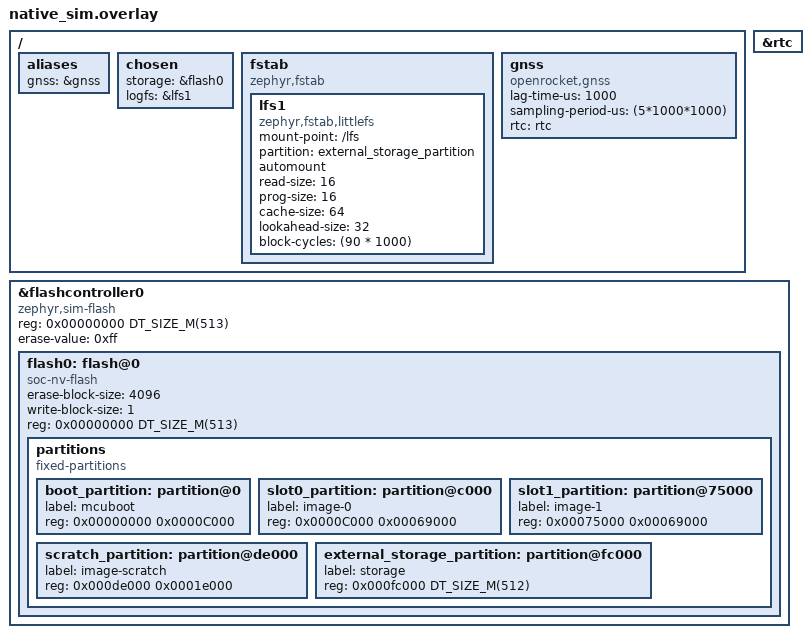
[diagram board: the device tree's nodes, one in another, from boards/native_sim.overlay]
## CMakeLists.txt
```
#-------------------------------------------------------------------------------
# Backplane Radio Module Application
#
# Copyright (c) 2023 Launch Initiative
# SPDX-License-Identifier: Apache-2.0

set(FSW_ROOT ${CMAKE_CURRENT_SOURCE_DIR}/../../..)
include(${FSW_ROOT}/cmake/Snippets.cmake)
include(${FSW_ROOT}/cmake/Autocoders.cmake)

AddCommonSnippets()

# Guarantee that core.conf is the default and first configuration file to be read
list(APPEND CONF_FILE ${CMAKE_CURRENT_SOURCE_DIR}/core.conf)

if (DEBUG)
    message(STATUS "Adding debug configuration")
    AddDebugSnippets()
    list(APPEND CONF_FILE ${CMAKE_CURRENT_SOURCE_DIR}/debug.conf)
endif ()

if (BOARD STREQUAL "native_sim")
    if (UNIX AND NOT APPLE)
        message(STATUS "Adding simulation configuration")
        AddSimSnippets()
        list(APPEND CONF_FILE ${CMAKE_CURRENT_SOURCE_DIR}/sim.conf)
    else ()
        message(FATAL_ERROR "Simulation is only supported on Linux systems")
    endif ()
endif ()

cmake_minimum_required(VERSION 3.13.1)
find_package(Zephyr REQUIRED HINTS $ENV{ZEPHYR_BASE})

project(radio-module LANGUAGES C CXX)

FILE(GLOB SOURCES src/*.c src/*.cpp)
target_include_directories(app PRIVATE include)
target_sources(app PRIVATE ${SOURCES})

AutocodeTypes()
AutocodeNetworkDefinitions()
add_dependencies(app ac_net_defs ac_types)
```

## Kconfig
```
# Copyright (c) 2021 Nordic Semiconductor ASA
# SPDX-License-Identifier: Apache-2.0
#
# This file is the application Kconfig entry point. All application Kconfig
# options can be defined here or included via other application Kconfig files.
# You can browse these options using the west targets menuconfig (terminal) or
# guiconfig (GUI).

menu "Zephyr"
source "Kconfig.zephyr"
endmenu

config MODULE_ID
    int "Module ID number"
    default 1
    help
      The module ID to use as the fourth octet in the IP address.

config GNSS_DATA_TX_INTERVAL
	int "GNSS data tx interval (miliseconds)"
	default 5000
	help
	  The interval at which GNSS data is transmitted through LoRa in milliseconds.

config RADIO_MODULE_CALLSIGN
	string "Radio module callsign"
	default "KD2YIE"
	help
	  Callsign string to broadcast over LoRa for the radio module.

config RADIO_MODULE_CALLSIGN_TX_INTERVAL_SECONDS
	int "Radio module callsign broadcast interval (seconds)"
	default 300
	range 1 86400
	help
	  Interval in seconds between LoRa callsign broadcasts.

module = APP_RADIO_MODULE
module-str = APP_RADIO_MODULE
source "subsys/logging/Kconfig.template.log_config"
```

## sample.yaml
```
sample:
  description: Radio Module
  name: radio-module
common:
  build_only: true
  integration_platforms:
    - radio_module
tests:
  radio_module.default: {}
  radio_module.debug:
    extra_overlay_confs:
      - debug.conf
```

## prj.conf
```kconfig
# Copyright (c) 2024 RIT Launch Initiative
# SPDX-License-Identifier: Apache-2.0

# CPP
CONFIG_CPP=y
CONFIG_REQUIRES_FULL_LIBCPP=y
CONFIG_STD_CPP20=y

CONFIG_F_CORE=y
CONFIG_CBPRINTF_FP_SUPPORT=y

# Filesystem
CONFIG_FILE_SYSTEM=y
CONFIG_FLASH_MAP=y
# OS
CONFIG_POLL=y
CONFIG_MAIN_STACK_SIZE=1024
CONFIG_STACK_USAGE=y

CONFIG_TIMESLICING=y
CONFIG_TIMESLICE_SIZE=50000
CONFIG_TIMESLICE_PRIORITY=0
CONFIG_THREAD_STACK_INFO=y

CONFIG_DYNAMIC_THREAD=y
# Max stack size for dynamic threads
CONFIG_DYNAMIC_THREAD_STACK_SIZE=512
CONFIG_DYNAMIC_THREAD_POOL_SIZE=4
CONFIG_LOG=y

# Networking
CONFIG_NETWORKING=y
CONFIG_NET_ARP_TABLE_SIZE=4
CONFIG_NET_CONTEXT_RCVTIMEO=y
CONFIG_NET_DEFAULT_IF_ETHERNET=y
CONFIG_NET_DRIVERS=y
CONFIG_NET_IPV4=y
CONFIG_NET_IPV6=n
CONFIG_NET_L2_ETHERNET=y
CONFIG_NET_L2_ETHERNET_MGMT=y
CONFIG_NET_MAX_CONN=10
CONFIG_NET_SOCKETS=y
CONFIG_NET_STATISTICS=y

# RNG (Needed for networking)
CONFIG_ENTROPY_GENERATOR=y
CONFIG_TEST_RANDOM_GENERATOR=y # TODO: See if its worth using STM32 HW RNG to remove warning

# IO
CONFIG_I2C=y
CONFIG_SPI=y
CONFIG_SENSOR=y

# GNSS
CONFIG_GNSS=y
CONFIG_GNSS_SATELLITES=y
CONFIG_GNSS_NMEA0183=y
CONFIG_UART_INTERRUPT_DRIVEN=y

# Misc
CONFIG_CBPRINTF_FP_SUPPORT=y
```

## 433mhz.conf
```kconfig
CONFIG_LICENSED_FREQUENCY=y
CONFIG_RADIO_MODULE_CALLSIGN="KD2YIE"
CONFIG_RADIO_MODULE_CALLSIGN_TX_INTERVAL_SECONDS=300
```

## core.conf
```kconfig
# Copyright (c) 2024 RIT Launch Initiative
# SPDX-License-Identifier: Apache-2.0

# CPP
CONFIG_CPP=y
CONFIG_REQUIRES_FULL_LIBCPP=y
CONFIG_STD_CPP20=y

CONFIG_F_CORE=y
CONFIG_F_CORE_DEVICE=y
CONFIG_F_CORE_NET=y
CONFIG_F_CORE_RADIO=y
CONFIG_F_CORE_STATE_MACHINE=y
CONFIG_F_CORE_OS=y
CONFIG_F_CORE_UTILS=y

CONFIG_CBPRINTF_FP_SUPPORT=y

# Filesystem
CONFIG_FILE_SYSTEM=y
CONFIG_FILE_SYSTEM_LITTLEFS=y
CONFIG_FS_LITTLEFS_FMP_DEV=y
CONFIG_FLASH=y
CONFIG_FLASH_MAP=y
CONFIG_FLASH_PAGE_LAYOUT=y

# Networking
CONFIG_ZVFS_OPEN_MAX=15
CONFIG_OBJ_CORE=y
CONFIG_NET_SOCKETS_OBJ_CORE=y

# OS
CONFIG_POLL=y
CONFIG_MAIN_STACK_SIZE=2048
CONFIG_STACK_USAGE=y

CONFIG_TIMESLICING=y
CONFIG_TIMESLICE_SIZE=20
CONFIG_TIMESLICE_PRIORITY=0
CONFIG_THREAD_STACK_INFO=y

CONFIG_DYNAMIC_THREAD=y
# Max stack size for dynamic threads
CONFIG_DYNAMIC_THREAD_STACK_SIZE=4096
CONFIG_DYNAMIC_THREAD_POOL_SIZE=4
CONFIG_LOG=y

# RNG (Needed for networking)
CONFIG_ENTROPY_GENERATOR=y
CONFIG_TEST_RANDOM_GENERATOR=y # TODO: See if its worth using STM32 HW RNG to remove warning

# IO
CONFIG_SPI=y

# GNSS
CONFIG_SENSOR=y
CONFIG_GNSS=y
CONFIG_GNSS_SATELLITES=y
CONFIG_GNSS_NMEA0183=y
CONFIG_UART_INTERRUPT_DRIVEN=y

# Suppress LORA LOG to only errors
CONFIG_LORA_LOG_LEVEL_ERR=y
```

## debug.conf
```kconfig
# Copyright (c) 2024 Launch Initiative
# SPDX-License-Identifier: Apache-2.0

# Compiler
CONFIG_DEBUG=y
CONFIG_DEBUG_OPTIMIZATIONS=y
CONFIG_DEBUG_THREAD_INFO=y
CONFIG_THREAD_RUNTIME_STATS=y

# Console
CONFIG_CONSOLE=y
CONFIG_CONSOLE_SUBSYS=y
CONFIG_SERIAL=y
CONFIG_UART_CONSOLE=y

# Shell (common)
CONFIG_SHELL=y
CONFIG_DEVICE_SHELL=y
CONFIG_FILE_SYSTEM_SHELL=y
CONFIG_GPIO_SHELL=y
CONFIG_I2C_SHELL=y
CONFIG_KERNEL_SHELL=y
CONFIG_NET_SHELL=y
CONFIG_SENSOR_SHELL=y
CONFIG_HEAP_MEM_POOL_SIZE=4096
CONFIG_SHELL_BACKEND_SERIAL_API_INTERRUPT_DRIVEN=y
CONFIG_SHELL_BACKEND_SERIAL_TX_RING_BUFFER_SIZE=4096
CONFIG_SHELL_BACKEND_SERIAL_RX_RING_BUFFER_SIZE=4096

# Logging
CONFIG_APP_RADIO_MODULE_LOG_LEVEL_DBG=y
CONFIG_LOG=y

# Networking
CONFIG_NET_STATISTICS=y
```

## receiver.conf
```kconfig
#CONFIG_GNSS=n
#CONFIG_GNSS_SATELLITES=n
#CONFIG_GNSS_NMEA0183=n
```

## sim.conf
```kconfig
CONFIG_OPENROCKET_SENSORS=y
CONFIG_OPENROCKET_DATA_FILE="../../../data/orksim_csv/omen.csv"
CONFIG_OPENROCKET_MS_BEFORE_LAUNCH=1000
CONFIG_OPENROCKET_SCALAR_TYPE_DOUBLE=y
CONFIG_OPENROCKET_EVENT_LOG=y
CONFIG_OPENROCKET_GNSS=y

CONFIG_RTC=y
CONFIG_RTC_EMUL=y
```

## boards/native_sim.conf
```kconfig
CONFIG_RTC_EMUL=y
```

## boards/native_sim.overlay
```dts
/ {
	aliases {
		gnss = &gnss;
		// Note that the RTC is already aliased in the native_sim dt
	};
    chosen {
		storage = &flash0;
		logfs = &lfs1;
    };

	fstab {
		compatible = "zephyr,fstab";

		lfs1: lfs1 {
			compatible = "zephyr,fstab,littlefs";
			mount-point = "/lfs";
			partition = <&external_storage_partition>;
			automount;

			// the binding reccomends defaults for these
			read-size = <16>;
			prog-size = <16>;
			cache-size = <64>; // may need to grow for optimization
			lookahead-size = <32>;
			block-cycles = <(90 * 1000)>;
			// the datasheet gives 100K P-E cycles
			// NOTE: this seems to default to 512 for the mounted filesystem
			// anyway
		};
	};


    gnss: gnss {
        status = "okay";
        compatible = "openrocket,gnss";
        lag-time-us = <1000>;
        sampling-period-us = <(5*1000*1000)>;
        rtc = <&rtc>;
    };
};

&rtc {
    status = "okay";
};

&flashcontroller0 {
	status = "okay";
	compatible = "zephyr,sim-flash";
	reg = <0x00000000 DT_SIZE_M(513)>;

	#address-cells = <1>;
	#size-cells = <1>;
	erase-value = <0xff>;

	flash0: flash@0 {
		status = "okay";
		compatible = "soc-nv-flash";
		erase-block-size = <4096>;
		write-block-size = <1>;
		reg = <0x00000000 DT_SIZE_M(513)>; // builtin stuff + external flash simulation

		partitions {
			compatible = "fixed-partitions";
			#address-cells = <1>;
			#size-cells = <1>;

			boot_partition: partition@0 {
				label = "mcuboot";
				reg = <0x00000000 0x0000C000>;
			};
			slot0_partition: partition@c000 {
				label = "image-0";
				reg = <0x0000C000 0x00069000>;
			};
			slot1_partition: partition@75000 {
				label = "image-1";
				reg = <0x00075000 0x00069000>;
			};
			scratch_partition: partition@de000 {
				label = "image-scratch";
				reg = <0x000de000 0x0001e000>;
			};
			external_storage_partition: partition@fc000 {
				label = "storage";
				reg = <0x000fc000 DT_SIZE_M(512)>;
			};
		};
	};
};
```

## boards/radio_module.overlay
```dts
/ {
	aliases {
		led0 = &red_led_1;
		led1 = &red_led_2;

		dbguart = &uart4;
		ubxlib-usart2 = &usart2;

		lora = &lora0;
		gnss = &maxm10s;

		rtc = &rtc;
	};
};
```

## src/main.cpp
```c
/*
* Copyright (c) 2024 RIT Launch Initiative
 *
 * SPDX-License-Identifier: Apache-2.0
 */

#include "c_radio_module.h"

#include <f_core/os/c_task.h>
#include <f_core/os/n_rtos.h>
#ifdef CONFIG_ARCH_POSIX
#include <nsi_main.h>
#include <signal.h>
#endif

LOG_MODULE_REGISTER(main);

#ifdef CONFIG_ARCH_POSIX
static volatile sig_atomic_t shutdownRequested = 0;

static void NativeSimSignalHandler(int) { shutdownRequested = 1; }
#endif

int main() {
#ifdef CONFIG_LICENSED_FREQUENCY
    LOG_INF("Radio module boot: 433 MHz build, callsign=%s", CONFIG_RADIO_MODULE_CALLSIGN);
#else
    LOG_INF("Radio module boot: 915 MHz build, callsign=%s", CONFIG_RADIO_MODULE_CALLSIGN);
#endif
    static CRadioModule radioModule{};

    radioModule.AddTenantsToTasks();
    radioModule.AddTasksToRtos();
    radioModule.SetupCallbacks();

    k_sched_time_slice_set(1000, 14); // 1ms slice for priority 14
    k_sched_time_slice_set(5000, 15); // 5ms slice for priority 15
    NRtos::StartRtos();

#ifdef CONFIG_ARCH_POSIX
    signal(SIGINT, NativeSimSignalHandler);
    signal(SIGTERM, NativeSimSignalHandler);

    while (!shutdownRequested) {
        k_sleep(K_MSEC(100));
    }

    NRtos::StopRtos();
    nsi_exit(0);
#endif

    return 0;
}
```

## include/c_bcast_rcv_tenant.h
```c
#ifndef C_BROADCAST_TENANT_H
#define C_BROADCAST_TENANT_H

#include <f_core/os/c_tenant.h>

#include <f_core/net/network/c_ipv4.h>
#include <f_core/net/transport/c_udp_socket.h>

class CBroadcastReceiveTenant : public CTenant {
public:
    explicit CBroadcastReceiveTenant(const char* name, const char *ipStr, const uint16_t listenPorts)
        : CTenant(name), ip(CIPv4{ipStr}), udp(CUdpSocket{ip, listenPorts, listenPorts})
    {
    }

    ~CBroadcastReceiveTenant() override = default;

    void Startup() override;

    void PostStartup() override;

    void Run() override;

private:
    CIPv4 ip;
    CUdpSocket udp;
};



#endif //C_BROADCAST_TENANT_H
```

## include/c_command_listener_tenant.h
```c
#ifndef C_COMMAND_LISTENER_TENANT
#define C_COMMAND_LISTENER_TENANT

#include "n_radio_module_types.h"

#include <f_core/os/c_tenant.h>
#include <f_core/net/network/c_ipv4.h>
#include <f_core/net/transport/c_udp_socket.h>
#include <f_core/device/c_gpio.h>

class CCommandListenerTenant : public CTenant {
public:
    explicit CCommandListenerTenant(const char* name, const char* ipStr, const uint16_t listenPort)
    : CTenant(name), ip(CIPv4{ip}), udp(CUdpSocket{ip, listenPort, listenPort}),
        gpios{CGpio(*DEVICE_DT_GET(DT_ALIAS(gpios1))), CGpio(*DEVICE_DT_GET(DT_ALIAS(gpios2))),
                CGpio(*DEVICE_DT_GET(DT_ALIAS(gpios3))), CGpio(*DEVICE_DT_GET(DT_ALIAS(gpios4)))} {}

    ~CCommandListenerTenant() override = default;

    void Startup() override;

    void PostStartup() override;

    void Run() override;

private:
    CIPv4 ip;
    CUdpSocket udp;
    const uint16_t listenPort;
    const CGpio gpios[4];
    
};

#endif // C_COMMAND_LISTENER_TENANT
```

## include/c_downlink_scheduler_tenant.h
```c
#pragma once

#include <f_core/os/c_runnable_tenant.h>
#include <f_core/radio/c_lora_frame_handler.h>
#include <f_core/state_machine/c_pad_flight_landing_state_machine.h>
#include <f_core/utils/c_hashmap.h>
#include <f_core/utils/c_soft_timer.h>
#include <memory>

class CDownlinkSchedulerTenant : public CRunnableTenant, public CPadFlightLandedStateMachine, public CLoraFrameHandler {
  public:
    /**
     * Constructor
     * @param loraDownlinkMessagePort The message port to send downlink frames to
     * @param telemetryMessagePortMap The map of telemetry port to message port for that telemetry
     * @param telemetryDownlinkTimes The map of telemetry port to downlink interval
     */
    explicit CDownlinkSchedulerTenant(CMessagePort<LaunchLoraFrame>& loraDownlinkMessagePort,
                                      const CHashMap<uint16_t, CMessagePort<LaunchLoraFrame>*>& telemetryMessagePortMap,
                                      CHashMap<uint16_t, k_timeout_t>& telemetryDownlinkTimes);

    /**
     * See parent docs
     */
    void HandleFrame(const ReceivedLaunchLoraFrame& rxFrame) override;

    /**
     * See parent docs
     */
    void Run() override;

  protected:
    /**
     * See parent docs
     */
    void PadRun() override;

    /**
     * See parent docs
     */
    void FlightRun() override;

    /**
     * See parent docs
     */
    void LandedRun() override;

    /**
     * See parent docs
     */
    void GroundRun() override;

  private:
    // Send a telemetry frame, piggybacking the flight phase onto GNSS frames
    // (port 12005) so the ground can observe the radio's state.
    void SendFrame(LaunchLoraFrame& frame);

    CMessagePort<LaunchLoraFrame>& loraDownlinkMessagePort;
    CHashMap<uint16_t, CMessagePort<LaunchLoraFrame>*> telemetryMessagePortMap;
    CHashMap<uint16_t, std::unique_ptr<CSoftTimer>> telemetryDownlinkTimers;

    bool gnssDownlinkAvailable = false;
};
```

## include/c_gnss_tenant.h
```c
#pragma once

#include "f_core/radio/c_lora_link.h"

#include <f_core/messaging/c_message_port.h>
#include <f_core/os/c_runnable_tenant.h>
#include <f_core/utils/c_soft_timer.h>
#include <n_autocoder_types.h>

class CGnssTenant : public CRunnableTenant {
  public:
    explicit CGnssTenant(const char* name, CMessagePort<LaunchLoraFrame>* loraTransmitPort,
                         CMessagePort<NTypes::GnssData>* dataLoggingPort)
        : CRunnableTenant(name), loraTransmitPort(*loraTransmitPort), dataLoggingPort(*dataLoggingPort) {}

    ~CGnssTenant() override = default;

    void Startup() override;

    void PostStartup() override;

    void Run() override;

  private:
    CSoftTimer transmitTimer{};
    CMessagePort<LaunchLoraFrame>& loraTransmitPort;
    CMessagePort<NTypes::GnssData>& dataLoggingPort;

    void sendGnssToLora() const;
};
```

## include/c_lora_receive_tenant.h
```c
#ifndef C_LORA_RECEIVE_TENANT_H
#define C_LORA_RECEIVE_TENANT_H


#include <c_lora_transmit_tenant.h>

#include <f_core/state_machine/c_pad_flight_landing_state_machine.h>
#include <f_core/os/c_runnable_tenant.h>
#include <f_core/net/network/c_ipv4.h>
#include <f_core/net/transport/c_udp_socket.h>
#include <f_core/device/c_gpio.h>
#include <f_core/utils/c_soft_timer.h>

void shutoffTimerExpirationFn(k_timer* timer);

class CLoraReceiveTenant : public CRunnableTenant, public CPadFlightLandedStateMachine {
public:
    explicit CLoraReceiveTenant(const char* name, CLoraTransmitTenant& loraTransmitTenant, const char* ip, const uint16_t srcPort)
        : CRunnableTenant(name), loraTransmitTenant(loraTransmitTenant), udp(CUdpSocket(CIPv4(ip), srcPort, srcPort)) {}

    /**
     * See Parent Docs
     */
    ~CLoraReceiveTenant() override = default;

    /**
     * See Parent Docs
     */
    void Startup() override;

    /**
     * See Parent Docs
     */
    void PostStartup() override;

    /**
     * See Parent Docs
     */
    void Run() override;

    /**
     * See Parent Docs
     */
    void PadRun() override;

    /**
     * See Parent Docs
     */
    void FlightRun() override;

    /**
     * See Parent Docs
     */
    void LandedRun() override;

private:
    CLoraTransmitTenant& loraTransmitTenant;
    CSoftTimer shutoffTimer{shutoffTimerExpirationFn, nullptr};

    CUdpSocket udp; 
    CGpio gpios[4] = {
        CGpio(GPIO_DT_SPEC_GET(DT_ALIAS(gpio0), gpios)),
        CGpio(GPIO_DT_SPEC_GET(DT_ALIAS(gpio1), gpios)),
        CGpio(GPIO_DT_SPEC_GET(DT_ALIAS(gpio2), gpios)),
        CGpio(GPIO_DT_SPEC_GET(DT_ALIAS(gpio3), gpios))
    };
    static constexpr int portOffset = 2;

    int receive(uint8_t *buffer, const int size, int *port) const;
};

#endif //C_LORA_RECEIVE_TENANT_H
```

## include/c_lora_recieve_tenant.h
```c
#ifndef C_LORA_RECEIVE_TENANT_H
#define C_LORA_RECEIVE_TENANT_H

#include "n_radio_module_types.h"

#include <f_core/os/c_tenant.h>
#include <f_core/net/device/c_lora.h>
#include <f_core/net/network/c_ipv4.h>
#include <f_core/net/transport/c_udp_socket.h>
#include <f_core/device/c_gpio.h>

class CLoraRecieveTenant : public CTenant {
public:
    explicit CLoraRecieveTenant(const char* name, CLora& lora, const char* ip, const uint16_t srcPort, MessagePort<NTypes::RadioBroadcastData>* loraTransmitPort)
        : CTenant(name), lora(lora), udp(CUdpSocket(CIPv4(ip), srcPort, srcPort), loraTransmitPort(*loraTransmitPort)) {}

    ~CLoraRecieveTenant() override = default;

    void Startup() override;

    void PostStartup() override;

    void Run() override;

private:
    CLora& lora;
    CUdpSocket udp;
    const CGpio gpios[4] = {CGpio(*DEVICE_DT_GET(DT_ALIAS(gpios0))), CGpio(*DEVICE_DT_GET(DT_ALIAS(gpios1))),
                CGpio(*DEVICE_DT_GET(DT_ALIAS(gpios2))), CGpio(*DEVICE_DT_GET(DT_ALIAS(gpios3)))};
    CMessagePort<NTypes::RadioBroadcastData>& loraTransmitPort;
};



#endif //C_LORA_RECEIVE_TENANT_H
```

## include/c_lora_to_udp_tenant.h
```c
#ifndef C_LORA_RECEIVE_TENANT_H
#define C_LORA_RECEIVE_TENANT_H

#include <f_core/os/c_tenant.h>

#include <f_core/net/device/c_lora.h>
#include <f_core/net/network/c_ipv4.h>
#include <f_core/net/transport/c_udp_socket.h>

class CLoraToUdpTenant : public CTenant {
public:
    explicit CLoraToUdpTenant(const char* name, CLora& lora, const char* ip, const uint16_t srcPort)
        : CTenant(name), lora(lora), udp(CUdpSocket(CIPv4(ip), srcPort, srcPort))
    {
    }

    ~CLoraToUdpTenant() override = default;

    void Startup() override;

    void PostStartup() override;

    void Run() override;

private:
    CLora& lora;
    CUdpSocket udp;
};



#endif //C_LORA_RECEIVE_TENANT_H
```

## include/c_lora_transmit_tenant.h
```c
#ifndef C_LORA_TRANSMIT_TENANT_H
#define C_LORA_TRANSMIT_TENANT_H

#include <n_autocoder_types.h>
#include <array>
#include <f_core/messaging/c_message_port.h>
#include <f_core/os/c_runnable_tenant.h>

#include <f_core/radio/c_lora.h>
#include <f_core/state_machine/c_pad_flight_landing_state_machine.h>
#include <f_core/utils/c_observer.h>
#include <f_core/utils/c_hashmap.h>

class CLoraTransmitTenant : public CRunnableTenant {
public:
    friend class CLoraReceiveTenant;

    explicit CLoraTransmitTenant(const char* name, CLora& lora,
                                 CMessagePort<NTypes::LoRaBroadcastData>* loraTransmitPort)
        : CRunnableTenant(name), lora(lora), loraTransmitPort(*loraTransmitPort) {}

    ~CLoraTransmitTenant() override = default;

    /**
     * See Parent Docs
     */
    void Startup() override;

    /**
     * See Parent Docs
     */
    void PostStartup() override;

    /**
     * See Parent Docs
     */
    void Run() override;


private:
    static constexpr uint8_t totalPortsListenedTo = 3;

    /**
     * Helper function for converting struct into a uint8_t buffer and transmitting over LoRa
     * @param[in] data Radio broadcast data structure
     * @return 0 on success, negative on error
     */
    int transmit(const NTypes::LoRaBroadcastData& data) const;

    /**
     * Helper function for reading from the transmit queue
     * @param[out] data Data received from queue to transmit over LoRa
     * @return True if new data needs to be transmitted, false otherwise
     */
    bool readTransmitQueue(NTypes::LoRaBroadcastData& data) const;

    CLora& lora;
    CMessagePort<NTypes::LoRaBroadcastData>& loraTransmitPort;
    CHashMap<uint16_t, NTypes::LoRaBroadcastData> portDataMap; // 254 bytes to leave room for port
    CHashMap<uint16_t, bool> padDataRequestedMap;
    // Maintain a list of ports we had at startup, in case anyone tries to be funny and add a port
    std::array<uint16_t, totalPortsListenedTo> listeningPortsList;
};

#endif //C_LORA_TRANSMIT_TENANT_H
```

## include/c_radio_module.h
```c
#pragma once

#include "c_downlink_scheduler_tenant.h"
#include "c_gnss_tenant.h"
#include "c_remote_gpio_handler.h"
#include "c_state_machine_updater.h"
#include "c_udp_listener_tenant.h"

// F-Core Includes
#include <f_core/c_project_configuration.h>
#include <f_core/device/c_rtc.h>
#include <f_core/messaging/c_latest_message_port.h>
#include <f_core/messaging/c_message_port.h>
#include <f_core/net/application/c_sntp_server_tenant.h>
#include <f_core/net/application/c_udp_alert_tenant.h>
#include <f_core/os/c_task.h>
#include <f_core/os/tenants/c_datalogger_tenant.h>
#include <f_core/radio/application/c_callsign_broadcast_tenant.h>
#include <f_core/radio/application/c_lora_tenant.h>
#include <f_core/radio/frame_handlers/c_frequency_change_handler.h>
#include <f_core/radio/frame_handlers/c_lora_frame_to_udp_handler.h>

// Autocoder Includes
#include <n_autocoder_network_defs.h>
#include <n_autocoder_types.h>

class CRadioModule : public CProjectConfiguration {
  public:
    /**
     * Constructor
     */
    CRadioModule();

    /**
     * See parent docs
     */
    void AddTenantsToTasks() override;

    /**
     * See parent docs
     */
    void AddTasksToRtos() override;

    /**
     * See parent docs
     */
    void SetupCallbacks() override;

    static rtc_time lastGnssUpdateTime;

  private:
    std::string ipAddrStr = CREATE_IP_ADDR(NNetworkDefs::RADIO_MODULE_IP_ADDR_BASE, 1, CONFIG_MODULE_ID);

    static constexpr uint16_t radioModuleSourcePort = NNetworkDefs::RADIO_BASE_PORT;
    static constexpr uint16_t powerModuleTelemetryPort = NNetworkDefs::POWER_MODULE_DOWNLINK_DATA_PORT;
    static constexpr uint16_t sensorModuleTelemetryPort = NNetworkDefs::SENSOR_MODULE_DOWNLINK_DATA_PORT;
    static constexpr uint16_t gnssTelemetryPort = NNetworkDefs::RADIO_MODULE_GNSS_DATA_PORT;

    // Devices
#ifndef CONFIG_ARCH_POSIX
    CLora lora;
#endif
    CRtc rtc{*DEVICE_DT_GET(DT_ALIAS(rtc))};

    // Message Ports
    CMessagePort<LaunchLoraFrame>& loraDownlinkMessagePort;
    CMessagePort<NTypes::GnssData>& gnssDataLogMessagePort;
    CLatestMessagePort<LaunchLoraFrame> sensorModuleTelemetryMessagePort;
    CLatestMessagePort<LaunchLoraFrame> powerModuleTelemetryMessagePort;
    CLatestMessagePort<LaunchLoraFrame> gnssTelemetryMessagePort;

    // Build the hashmap here for passing into downlink scheduler tenant
    CHashMap<uint16_t, CMessagePort<LaunchLoraFrame>*> telemetryMessagePortMap = {
        {sensorModuleTelemetryPort, &sensorModuleTelemetryMessagePort},
        {powerModuleTelemetryPort, &powerModuleTelemetryMessagePort},
        {gnssTelemetryPort, &gnssTelemetryMessagePort}};

    // Build downlink timer map here so easy to add new telemetry along with above hashmap,
    // and have downlink scheduler figure out starting the timers itself
    CHashMap<uint16_t, k_timeout_t> telemetryDownlinkTimes = {{sensorModuleTelemetryPort, K_SECONDS(5)},
                                                              {powerModuleTelemetryPort, K_SECONDS(10)},
                                                              {gnssTelemetryPort, K_SECONDS(5)}};

    // Tenants
    CGnssTenant gnssTenant{"GNSS Tenant", &gnssTelemetryMessagePort, &gnssDataLogMessagePort};
    CCallsignBroadcastTenant callsignBroadcastTenant{CONFIG_RADIO_MODULE_CALLSIGN,
                                                     K_SECONDS(CONFIG_RADIO_MODULE_CALLSIGN_TX_INTERVAL_SECONDS),
                                                     loraDownlinkMessagePort, 0};

    CUdpListenerTenant sensorModuleListenerTenant{"Sensor Module Listener Tenant", ipAddrStr.c_str(),
                                                  sensorModuleTelemetryPort, &sensorModuleTelemetryMessagePort};

    CUdpListenerTenant powerModuleListenerTenant{"Power Module Listener Tenant", ipAddrStr.c_str(),
                                                 powerModuleTelemetryPort, &powerModuleTelemetryMessagePort};

    CSntpServerTenant sntpServerTenant = *CSntpServerTenant::GetInstance(rtc, CIPv4(ipAddrStr.c_str()));

    CDownlinkSchedulerTenant downlinkSchedulerTenant{loraDownlinkMessagePort, telemetryMessagePortMap,
                                                     telemetryDownlinkTimes};

    CUdpAlertTenant alertTenant{"Alert Tenant", ipAddrStr.c_str(), NNetworkDefs::ALERT_PORT};

#ifndef CONFIG_ARCH_POSIX
    CLoraTenant loraTenant{lora, loraDownlinkMessagePort};
#endif
    CDataLoggerTenant<NTypes::GnssData> dataLoggerTenant{
        "Data Logger Tenant", "/lfs/gps_data.bin", LogMode::Growing, 0, gnssDataLogMessagePort, K_SECONDS(15), 5};

    CStateMachineUpdater stateMachineUpdater;

    // LoRa Handlers
    CRemoteGpioHandler remoteGpioHandler{loraDownlinkMessagePort};
    CLoraFrameToUdpHandler loraToUdpHandler{ipAddrStr.c_str(), radioModuleSourcePort};
    CFrequencyChangeHandler frequencyChangeHandler{lora, loraDownlinkMessagePort,
                                                   NNetworkDefs::RADIO_MODULE_FREQUENCY_CHANGE_RESPONSE_PORT};

    // Tasks
    CTask networkingTask{"Networking Task", 14, 3072, 5};
    CTask gnssTask{"GNSS Task", 15, 1024, 2000};
    CTask dataLoggingTask{"Data Logging Task", 15, 2048, 10};
    CTask loraTask{"LoRa Task", 14, 2048, 10};
};
```

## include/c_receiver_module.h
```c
#ifdef CONFIG_RADIO_MODULE_RECEIVER
#ifndef C_RECEIVER_MODULE_H
#define C_RECEIVER_MODULE_H

#include "n_radio_module_types.h"
#include "c_gnss_tenant.h"
#include "c_lora_receive_tenant.h"
#include "c_lora_transmit_tenant.h"
#include "c_udp_listener_tenant.h"

// F-Core Includes
#include <f_core/c_project_configuration.h>
#include <f_core/messaging/c_message_port.h>
#include <f_core/os/c_task.h>
#include <f_core/radio/c_lora.h>

#include <n_autocoder_network_defs.h>

class CReceiverModule : public CProjectConfiguration {
public:
    /**
     * Constructor
     */
    CReceiverModule();

    /**
     * See parent docs
     */
    void AddTenantsToTasks() override;

    /**
     * See parent docs
     */
    void AddTasksToRtos() override;

    /**
     * See parent docs
     */
    void SetupCallbacks() override;

private:
    const char* ipAddrStr = (CREATE_IP_ADDR(NNetworkDefs::RADIO_MODULE_IP_ADDR_BASE, 1, CONFIG_MODULE_ID)).c_str();
    static constexpr uint16_t radioModuleCommandPort = NNetworkDefs::RADIO_MODULE_COMMAND_PORT;
    static constexpr uint16_t radioModuleDataRequestPort = NNetworkDefs::RADIO_MODULE_DATA_REQUEST_PORT;

    // Devices
    CLora lora;

    // Message Ports
    CMessagePort<NTypes::RadioBroadcastData>& loraBroadcastMessagePort;
    CMessagePort<NTypes::RadioBroadcastData>& udpBroadcastMessagePort;

    // Tenants
    CLoraTransmitTenant loraTransmitTenant{"LoRa Transmit Tenant", lora, &loraBroadcastMessagePort};
    CUdpListenerTenant commandListenerTenant{"Radio Module Command Listener Tenant", ipAddrStr, radioModuleCommandPort, &loraBroadcastMessagePort};
    CUdpListenerTenant dataRequestListenerTenant{"Radio Module Data Request Listener Tenant", ipAddrStr, radioModuleDataRequestPort, &loraBroadcastMessagePort};

    CLoraReceiveTenant loraReceiveTenant{"LoRa Receive Tenant", loraTransmitTenant, ipAddrStr, NNetworkDefs::RADIO_BASE_PORT};

    // Tasks
    CTask networkingTask{"UDP Listener Task", 15, 1024, 0};
    CTask loraTask{"LoRa Rx Task", 15, 2048, 0};
};

#endif //C_RECEIVER_MODULE_H
#endif //RADIO_MODULE_RECEIVER
```

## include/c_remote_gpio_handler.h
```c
#pragma once

#include <f_core/device/c_gpio.h>
#include <f_core/radio/c_lora_frame_handler.h>
#include <zephyr/drivers/gpio.h>

class CRemoteGpioHandler : public CLoraFrameHandler {
  public:
    explicit CRemoteGpioHandler(CMessagePort<LaunchLoraFrame>& loraDownlinkMessagePort)
        : loraDownlinkMessagePort(loraDownlinkMessagePort) {}

    /**
     * Handle incoming GPIO command frame
     * @param rxFrame Frame containing GPIO command
     */
    void HandleFrame(const ReceivedLaunchLoraFrame& rxFrame) override;

  private:
    CGpio gpios[4] = {
        CGpio(GPIO_DT_SPEC_GET(DT_ALIAS(gpio0), gpios)),
        CGpio(GPIO_DT_SPEC_GET(DT_ALIAS(gpio1), gpios)),
        CGpio(GPIO_DT_SPEC_GET(DT_ALIAS(gpio2), gpios)),
        CGpio(GPIO_DT_SPEC_GET(DT_ALIAS(gpio3), gpios)),
    };

    CMessagePort<LaunchLoraFrame>& loraDownlinkMessagePort;

    /**
     * Set GPIO states based on command byte
     * @param commandByte Bitfield representing GPIO states
     */
    void setGpios(const uint8_t commandByte);

    /**
     * Transmit current GPIO states back over LoRa
     */
    void transmitStatus() const;
};
```

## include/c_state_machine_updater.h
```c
#pragma once

#include <f_core/utils/c_observer.h>

class CStateMachineUpdater : public CObserver {
  public:
    /**
     * Constructor
     */
    CStateMachineUpdater() = default;

    /**
     * Destructor
     */
    ~CStateMachineUpdater() override = default;

    /**
     * See parent docs
     */
    void Notify(void *ctx) override;
};
```
